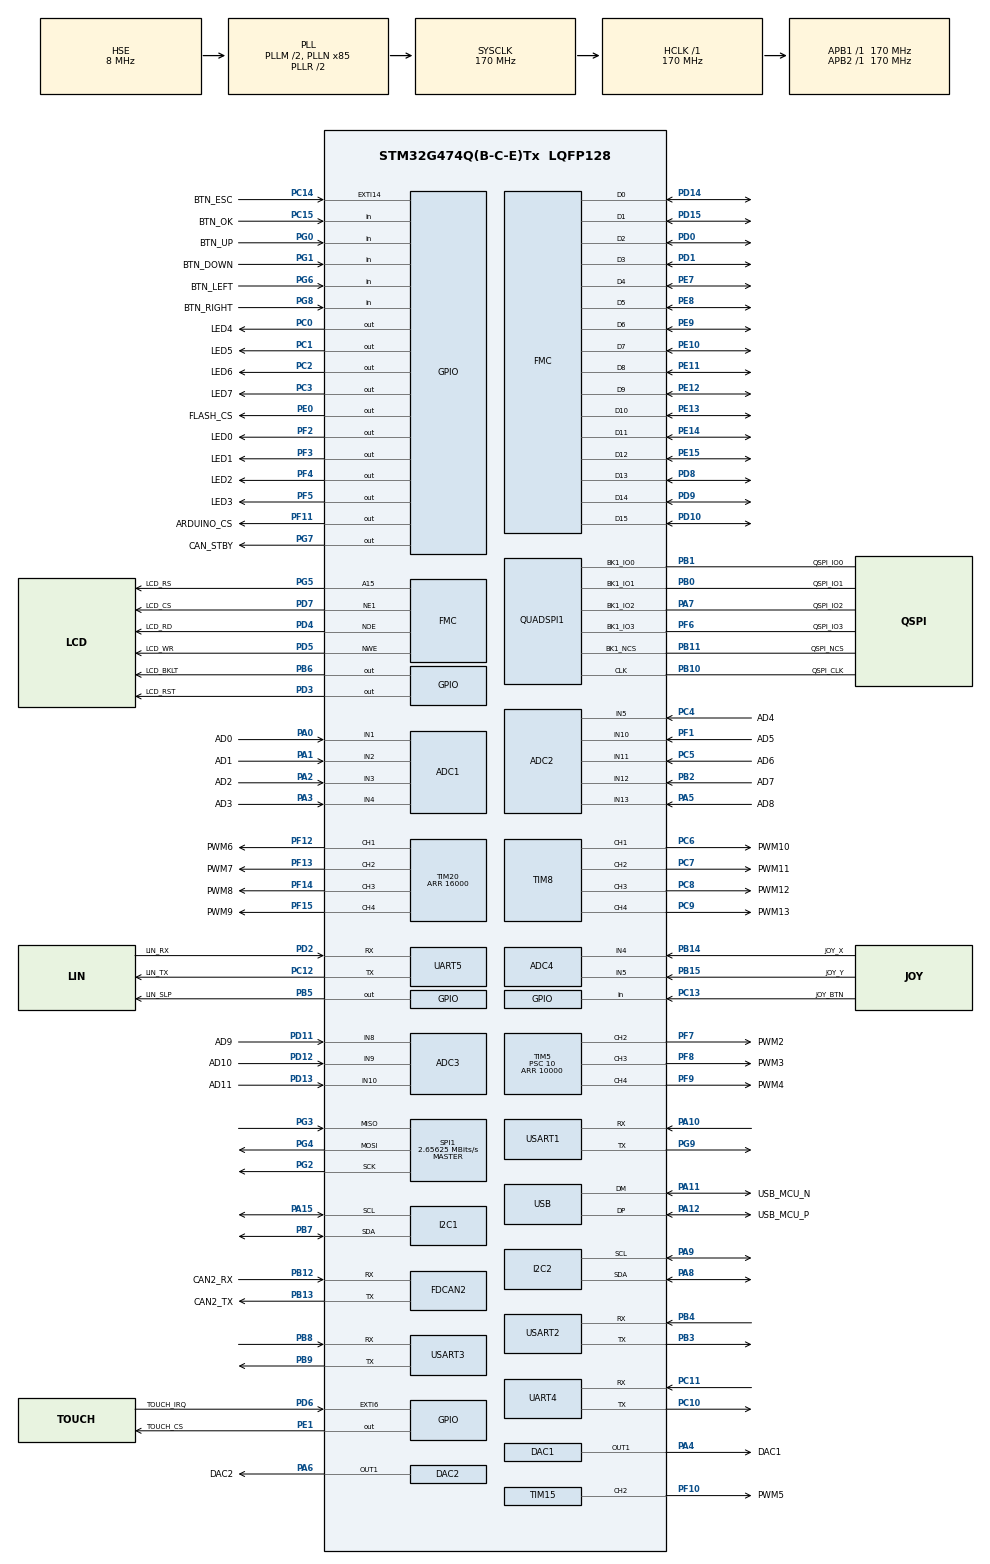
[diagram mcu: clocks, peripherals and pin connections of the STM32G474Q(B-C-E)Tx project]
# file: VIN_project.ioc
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ADC1.Channel-0\#ChannelRegularConversion=ADC_CHANNEL_2
ADC1.NbrOfConversionFlag=1
ADC1.OffsetNumber-0\#ChannelRegularConversion=ADC_OFFSET_NONE
ADC1.Rank-0\#ChannelRegularConversion=1
ADC1.SamplingTime-0\#ChannelRegularConversion=ADC_SAMPLETIME_2CYCLES_5
ADC1.master=1
ADC2.Channel-0\#ChannelRegularConversion=ADC_CHANNEL_5
ADC2.NbrOfConversionFlag=1
ADC2.OffsetNumber-0\#ChannelRegularConversion=ADC_OFFSET_NONE
ADC2.Rank-0\#ChannelRegularConversion=1
ADC2.SamplingTime-0\#ChannelRegularConversion=ADC_SAMPLETIME_2CYCLES_5
ADC3.Channel-1\#ChannelRegularConversion=ADC_CHANNEL_8
ADC3.NbrOfConversionFlag=1
ADC3.OffsetNumber-1\#ChannelRegularConversion=ADC_OFFSET_NONE
ADC3.Rank-1\#ChannelRegularConversion=1
ADC3.SamplingTime-1\#ChannelRegularConversion=ADC_SAMPLETIME_2CYCLES_5
ADC3.master=1
ADC4.Channel-0\#ChannelRegularConversion=ADC_CHANNEL_4
ADC4.Channel-1\#ChannelRegularConversion=ADC_CHANNEL_5
ADC4.ContinuousConvMode=DISABLE
ADC4.DMAContinuousRequests=DISABLE
ADC4.DiscontinuousConvMode=ENABLE
ADC4.EOCSelection=ADC_EOC_SINGLE_CONV
ADC4.NbrOfConversion=2
ADC4.NbrOfConversionFlag=1
ADC4.OffsetNumber-0\#ChannelRegularConversion=ADC_OFFSET_NONE
ADC4.OffsetNumber-1\#ChannelRegularConversion=ADC_OFFSET_NONE
ADC4.Overrun=ADC_OVR_DATA_OVERWRITTEN
ADC4.Rank-0\#ChannelRegularConversion=1
ADC4.Rank-1\#ChannelRegularConversion=2
ADC4.SamplingTime-0\#ChannelRegularConversion=ADC_SAMPLETIME_92CYCLES_5
ADC4.SamplingTime-1\#ChannelRegularConversion=ADC_SAMPLETIME_92CYCLES_5
Dma.Request0=USART1_RX
Dma.Request1=USART1_TX
Dma.USART1_RX.0.Direction=DMA_PERIPH_TO_MEMORY
Dma.USART1_RX.0.EventEnable=DISABLE
Dma.USART1_RX.0.Instance=DMA1_Channel1
Dma.USART1_RX.0.MemDataAlignment=DMA_MDATAALIGN_BYTE
Dma.USART1_RX.0.MemInc=DMA_MINC_ENABLE
Dma.USART1_RX.0.Mode=DMA_NORMAL
Dma.USART1_RX.0.PeriphDataAlignment=DMA_PDATAALIGN_BYTE
Dma.USART1_RX.0.PeriphInc=DMA_PINC_DISABLE
Dma.USART1_RX.0.Polarity=HAL_DMAMUX_REQ_GEN_RISING
Dma.USART1_RX.0.Priority=DMA_PRIORITY_LOW
Dma.USART1_RX.0.RequestNumber=1
Dma.USART1_RX.0.SignalID=NONE
Dma.USART1_RX.0.SyncEnable=DISABLE
Dma.USART1_RX.0.SyncPolarity=HAL_DMAMUX_SYNC_NO_EVENT
Dma.USART1_RX.0.SyncRequestNumber=1
Dma.USART1_RX.0.SyncSignalID=NONE
Dma.USART1_TX.1.Direction=DMA_MEMORY_TO_PERIPH
Dma.USART1_TX.1.EventEnable=DISABLE
Dma.USART1_TX.1.Instance=DMA1_Channel2
Dma.USART1_TX.1.MemDataAlignment=DMA_MDATAALIGN_BYTE
Dma.USART1_TX.1.MemInc=DMA_MINC_ENABLE
Dma.USART1_TX.1.Mode=DMA_NORMAL
Dma.USART1_TX.1.PeriphDataAlignment=DMA_PDATAALIGN_BYTE
Dma.USART1_TX.1.PeriphInc=DMA_PINC_DISABLE
Dma.USART1_TX.1.Polarity=HAL_DMAMUX_REQ_GEN_RISING
Dma.USART1_TX.1.Priority=DMA_PRIORITY_LOW
Dma.USART1_TX.1.RequestNumber=1
Dma.USART1_TX.1.SignalID=NONE
Dma.USART1_TX.1.SyncEnable=DISABLE
Dma.USART1_TX.1.SyncPolarity=HAL_DMAMUX_SYNC_NO_EVENT
Dma.USART1_TX.1.SyncRequestNumber=1
Dma.USART1_TX.1.SyncSignalID=NONE
FMC.AddressSetupTime1=1
FMC.BusTurnAroundDuration1=1
FMC.DataHoldTime1=1
FMC.DataSetupTime1=1
FMC.ExtendedMode1=FMC_EXTENDED_MODE_DISABLE
I2C1.Timing=0x30A0A7FB
I2C2.Timing=0x30A0A7FB
Mcu.Family=STM32G4
Mcu.Name=STM32G474Q(B-C-E)Tx
Mcu.Package=LQFP128
NVIC.DMA1_Channel1_IRQn=true\:0\:0\:false\:false\:true\:false\:true\:true
NVIC.DMA1_Channel2_IRQn=true\:0\:0\:false\:false\:true\:false\:true\:true
NVIC.EXTI15_10_IRQn=true\:0\:0\:true\:false\:true\:true\:true\:true
NVIC.EXTI9_5_IRQn=true\:0\:0\:false\:false\:true\:true\:true\:true
NVIC.PriorityGroup=NVIC_PRIORITYGROUP_4
NVIC.TIM6_DAC_IRQn=true\:15\:0\:true\:false\:true\:true\:true\:true
NVIC.USB_LP_IRQn=true\:0\:0\:false\:false\:true\:false\:true\:true
PA0.GPIO_Label=AD0
PA0.Mode=IN1-Single-Ended
PA0.Signal=ADC1_IN1
PA1.GPIO_Label=AD1
PA1.Mode=IN2-Single-Ended
PA1.Signal=ADC1_IN2
PA10.Mode=Asynchronous
PA10.Signal=USART1_RX
PA11.GPIO_Label=USB_MCU_N
PA11.Mode=Device
PA11.Signal=USB_DM
PA12.GPIO_Label=USB_MCU_P
PA12.Mode=Device
PA12.Signal=USB_DP
PA13.GPIO_Label=SWDIO
PA13.Mode=Trace_Synchro_4bits_SW
PA13.Signal=SYS_JTMS-SWDIO
PA14.GPIO_Label=SWCLK
PA14.Mode=Trace_Synchro_4bits_SW
PA14.Signal=SYS_JTCK-SWCLK
PA15.Mode=I2C
PA15.Signal=I2C1_SCL
PA2.GPIO_Label=AD2
PA2.Mode=IN3-Single-Ended
PA2.Signal=ADC1_IN3
PA3.GPIO_Label=AD3
PA3.Mode=IN4-Single-Ended
PA3.Signal=ADC1_IN4
PA4.GPIO_Label=DAC1
PA4.Signal=COMP_DAC11_group
PA5.GPIO_Label=AD8
PA5.Mode=IN13-Single-Ended
PA5.Signal=ADC2_IN13
PA6.GPIO_Label=DAC2
PA6.Signal=COMP_DAC21_group
PA7.GPIO_Label=QSPI_IO2
PA7.Mode=Single Bank 1
PA7.Signal=QUADSPI1_BK1_IO2
PA8.GPIO_Pu=GPIO_PULLUP
PA8.Mode=I2C
PA8.Signal=I2C2_SDA
PA9.GPIO_Pu=GPIO_PULLUP
PA9.Mode=I2C
PA9.Signal=I2C2_SCL
PB0.GPIO_Label=QSPI_IO1
PB0.Mode=Single Bank 1
PB0.Signal=QUADSPI1_BK1_IO1
PB1.GPIO_Label=QSPI_IO0
PB1.Mode=Single Bank 1
PB1.Signal=QUADSPI1_BK1_IO0
PB10.GPIO_Label=QSPI_CLK
PB10.Mode=Single Bank 1
PB10.Signal=QUADSPI1_CLK
PB11.GPIO_Label=QSPI_NCS
PB11.Mode=Single Bank 1
PB11.Signal=QUADSPI1_BK1_NCS
PB12.GPIO_Label=CAN2_RX
PB12.Mode=FDCAN_Activate
PB12.Signal=FDCAN2_RX
PB13.GPIO_Label=CAN2_TX
PB13.Mode=FDCAN_Activate
PB13.Signal=FDCAN2_TX
PB14.GPIO_Label=JOY_X
PB14.Mode=IN4-Single-Ended
PB14.Signal=ADC4_IN4
PB15.GPIO_Label=JOY_Y
PB15.Mode=IN5-Single-Ended
PB15.Signal=ADC4_IN5
PB2.GPIO_Label=AD7
PB2.Mode=IN12-Single-Ended
PB2.Signal=ADC2_IN12
PB3.Mode=Asynchronous
PB3.Signal=USART2_TX
PB4.Mode=Asynchronous
PB4.Signal=USART2_RX
PB5.GPIO_Label=LIN_SLP
PB5.Signal=GPIO_Output
PB6.GPIO_Label=LCD_BKLT
PB6.Signal=GPIO_Output
PB7.Mode=I2C
PB7.Signal=I2C1_SDA
PB8-BOOT0.Mode=Asynchronous
PB8-BOOT0.Signal=USART3_RX
PB9.Mode=Asynchronous
PB9.Signal=USART3_TX
PC0.GPIO_Label=LED4
PC0.Signal=GPIO_Output
PC1.GPIO_Label=LED5
PC1.Signal=GPIO_Output
PC10.Mode=Asynchronous
PC10.Signal=UART4_TX
PC11.Mode=Asynchronous
PC11.Signal=UART4_RX
PC12.GPIO_Label=LIN_TX
PC12.Mode=Asynchronous
PC12.Signal=UART5_TX
PC13.GPIO_Label=JOY_BTN
PC13.GPIO_PuPd=GPIO_PULLUP
PC13.Signal=GPIO_Input
PC14-OSC32_IN.GPIO_Label=BTN_ESC
PC14-OSC32_IN.GPIO_ModeDefaultEXTI=GPIO_MODE_IT_FALLING
PC14-OSC32_IN.GPIO_PuPd=GPIO_PULLUP
PC14-OSC32_IN.Signal=GPXTI14
PC15-OSC32_OUT.GPIO_Label=BTN_OK
PC15-OSC32_OUT.GPIO_PuPd=GPIO_PULLUP
PC15-OSC32_OUT.Signal=GPIO_Input
PC2.GPIO_Label=LED6
PC2.Signal=GPIO_Output
PC3.GPIO_Label=LED7
PC3.Signal=GPIO_Output
PC4.GPIO_Label=AD4
PC4.Mode=IN5-Single-Ended
PC4.Signal=ADC2_IN5
PC5.GPIO_Label=AD6
PC5.Mode=IN11-Single-Ended
PC5.Signal=ADC2_IN11
PC6.GPIO_Label=PWM10
PC6.Signal=S_TIM8_CH1
PC7.GPIO_Label=PWM11
PC7.Signal=S_TIM8_CH2
PC8.GPIO_Label=PWM12
PC8.Signal=S_TIM8_CH3
PC9.GPIO_Label=PWM13
PC9.Signal=S_TIM8_CH4
PD0.Signal=FMC_D2_DA2
PD1.Signal=FMC_D3_DA3
PD10.Signal=FMC_D15_DA15
PD11.GPIO_Label=AD9
PD11.GPIO_Mode=GPIO_MODE_ANALOG
PD11.GPIO_PuPd=GPIO_NOPULL
PD11.Mode=IN8-Single-Ended
PD11.Signal=ADC3_IN8
PD12.GPIO_Label=AD10
PD12.GPIO_Mode=GPIO_MODE_ANALOG
PD12.GPIO_PuPd=GPIO_NOPULL
PD12.Mode=IN9-Single-Ended
PD12.Signal=ADC3_IN9
PD13.GPIO_Label=AD11
PD13.GPIO_Mode=GPIO_MODE_ANALOG
PD13.GPIO_PuPd=GPIO_NOPULL
PD13.Mode=IN10-Single-Ended
PD13.Signal=ADC3_IN10
PD14.Signal=FMC_D0_DA0
PD15.Signal=FMC_D1_DA1
PD2.GPIO_Label=LIN_RX
PD2.Mode=Asynchronous
PD2.Signal=UART5_RX
PD3.GPIO_Label=LCD_RST
PD3.Signal=GPIO_Output
PD4.GPIO_Label=LCD_RD
PD4.Signal=FMC_NOE
PD5.GPIO_Label=LCD_WR
PD5.Signal=FMC_NWE
PD6.GPIO_Label=TOUCH_IRQ
PD6.GPIO_ModeDefaultEXTI=GPIO_MODE_IT_FALLING
PD6.GPIO_PuPd=GPIO_PULLUP
PD6.Signal=GPXTI6
PD7.GPIO_Label=LCD_CS
PD7.Mode=NorPsramChipSelect1_1
PD7.Signal=FMC_NE1
PD8.Signal=FMC_D13_DA13
PD9.Signal=FMC_D14_DA14
PE0.GPIO_Label=FLASH_CS
PE0.Signal=GPIO_Output
PE1.GPIO_Label=TOUCH_CS
PE1.GPIO_PuPd=GPIO_PULLUP
PE1.GPIO_Speed=GPIO_SPEED_FREQ_HIGH
PE1.PinState=GPIO_PIN_SET
PE1.Signal=GPIO_Output
PE10.Signal=FMC_D7_DA7
PE11.Signal=FMC_D8_DA8
PE12.Signal=FMC_D9_DA9
PE13.Signal=FMC_D10_DA10
PE14.Signal=FMC_D11_DA11
PE15.Signal=FMC_D12_DA12
PE2.Mode=Trace_Synchro_4bits_SW
PE2.Signal=SYS_TRACECLK
PE3.Mode=Trace_Synchro_4bits_SW
PE3.Signal=SYS_TRACED0
PE4.Mode=Trace_Synchro_4bits_SW
PE4.Signal=SYS_TRACED1
PE5.Mode=Trace_Synchro_4bits_SW
PE5.Signal=SYS_TRACED2
PE6.Mode=Trace_Synchro_4bits_SW
PE6.Signal=SYS_TRACED3
PE7.Signal=FMC_D4_DA4
PE8.Signal=FMC_D5_DA5
PE9.Signal=FMC_D6_DA6
PF0-OSC_IN.GPIO_Label=MCI
PF0-OSC_IN.Mode=HSE-External-Clock-Source
PF0-OSC_IN.Signal=RCC_OSC_IN
PF1-OSC_OUT.GPIO_Label=AD5
PF1-OSC_OUT.Mode=IN10-Single-Ended
PF1-OSC_OUT.Signal=ADC2_IN10
PF10.GPIO_Label=PWM5
PF10.Signal=S_TIM15_CH2
PF11.GPIO_Label=ARDUINO_CS
PF11.Signal=GPIO_Output
PF12.GPIO_Label=PWM6
PF12.Mode=PWM Generation1 CH1
PF12.Signal=TIM20_CH1
PF13.GPIO_Label=PWM7
PF13.Signal=S_TIM20_CH2
PF14.GPIO_Label=PWM8
PF14.Signal=S_TIM20_CH3
PF15.GPIO_Label=PWM9
PF15.Signal=S_TIM20_CH4
PF2.GPIO_Label=LED0
PF2.GPIO_Speed=GPIO_SPEED_FREQ_VERY_HIGH
PF2.Signal=GPIO_Output
PF3.GPIO_Label=LED1
PF3.Signal=GPIO_Output
PF4.GPIO_Label=LED2
PF4.Signal=GPIO_Output
PF5.GPIO_Label=LED3
PF5.Signal=GPIO_Output
PF6.GPIO_Label=QSPI_IO3
PF6.Mode=Single Bank 1
PF6.Signal=QUADSPI1_BK1_IO3
PF7.GPIO_Label=PWM2
PF7.Signal=S_TIM5_CH2
PF8.GPIO_Label=PWM3
PF8.Signal=S_TIM5_CH3
PF9.GPIO_Label=PWM4
PF9.Signal=S_TIM5_CH4
PG0.GPIO_Label=BTN_UP
PG0.GPIO_PuPd=GPIO_PULLUP
PG0.Signal=GPIO_Input
PG1.GPIO_Label=BTN_DOWN
PG1.GPIO_PuPd=GPIO_PULLUP
PG1.Signal=GPIO_Input
PG2.Mode=Full_Duplex_Master
PG2.Signal=SPI1_SCK
PG3.Mode=Full_Duplex_Master
PG3.Signal=SPI1_MISO
PG4.Mode=Full_Duplex_Master
PG4.Signal=SPI1_MOSI
PG5.GPIO_Label=LCD_RS
PG5.Signal=FMC_A15
PG6.GPIO_Label=BTN_LEFT
PG6.GPIO_PuPd=GPIO_PULLUP
PG6.Signal=GPIO_Input
PG7.GPIO_Label=CAN_STBY
PG7.Signal=GPIO_Output
PG8.GPIO_Label=BTN_RIGHT
PG8.GPIO_PuPd=GPIO_PULLUP
PG8.Signal=GPIO_Input
PG9.Mode=Asynchronous
PG9.Signal=USART1_TX
ProjectManager.HeapSize=0x200
ProjectManager.StackSize=0x400
ProjectManager.TargetToolchain=STM32CubeIDE
RCC.ADC12Freq_Value=170000000
RCC.ADC345Freq_Value=170000000
RCC.AHBFreq_Value=170000000
RCC.APB1Freq_Value=170000000
RCC.APB1TimFreq_Value=170000000
RCC.APB2Freq_Value=170000000
RCC.APB2TimFreq_Value=170000000
RCC.CK48CLockSelection=RCC_USBCLKSOURCE_HSI48
RCC.CortexFreq_Value=170000000
RCC.EXTERNAL_CLOCK_VALUE=12288000
RCC.HCLKFreq_Value=170000000
RCC.HSE_VALUE=8000000
RCC.HSI48_VALUE=48000000
RCC.HSI_VALUE=16000000
RCC.LSE_VALUE=32768
RCC.PLLM=RCC_PLLM_DIV2
RCC.PLLN=85
RCC.PLLQ=RCC_PLLQ_DIV6
RCC.PLLSourceVirtual=RCC_PLLSOURCE_HSE
RCC.SYSCLKFreq_VALUE=170000000
RCC.SYSCLKSource=RCC_SYSCLKSOURCE_PLLCLK
RCC.USBFreq_Value=48000000
RCC.VCOOutputFreq_Value=340000000
SH.COMP_DAC11_group.0=DAC1_OUT1,DAC_OUT1
SH.COMP_DAC21_group.0=DAC2_OUT1,DAC_OUT1
SH.FMC_A15.0=FMC_A15,A15_1
SH.FMC_D0_DA0.0=FMC_D0,16b-d1
SH.FMC_D10_DA10.0=FMC_D10,16b-d1
SH.FMC_D11_DA11.0=FMC_D11,16b-d1
SH.FMC_D12_DA12.0=FMC_D12,16b-d1
SH.FMC_D13_DA13.0=FMC_D13,16b-d1
SH.FMC_D14_DA14.0=FMC_D14,16b-d1
SH.FMC_D15_DA15.0=FMC_D15,16b-d1
SH.FMC_D1_DA1.0=FMC_D1,16b-d1
SH.FMC_D2_DA2.0=FMC_D2,16b-d1
SH.FMC_D3_DA3.0=FMC_D3,16b-d1
SH.FMC_D4_DA4.0=FMC_D4,16b-d1
SH.FMC_D5_DA5.0=FMC_D5,16b-d1
SH.FMC_D6_DA6.0=FMC_D6,16b-d1
SH.FMC_D7_DA7.0=FMC_D7,16b-d1
SH.FMC_D8_DA8.0=FMC_D8,16b-d1
SH.FMC_D9_DA9.0=FMC_D9,16b-d1
SH.FMC_NOE.0=FMC_NOE,Lcd1
SH.FMC_NWE.0=FMC_NWE,Lcd1
SH.S_TIM15_CH2.0=TIM15_CH2,PWM Generation2 CH2
SH.S_TIM20_CH2.0=TIM20_CH2,PWM Generation2 CH2
SH.S_TIM20_CH3.0=TIM20_CH3,PWM Generation3 CH3
SH.S_TIM20_CH4.0=TIM20_CH4,PWM Generation4 CH4
SH.S_TIM5_CH2.0=TIM5_CH2,PWM Generation2 CH2
SH.S_TIM5_CH3.0=TIM5_CH3,PWM Generation3 CH3
SH.S_TIM5_CH4.0=TIM5_CH4,PWM Generation4 CH4
SH.S_TIM8_CH1.0=TIM8_CH1,PWM Generation1 CH1
SH.S_TIM8_CH2.0=TIM8_CH2,PWM Generation2 CH2
SH.S_TIM8_CH3.0=TIM8_CH3,PWM Generation3 CH3
SH.S_TIM8_CH4.0=TIM8_CH4,PWM Generation4 CH4
SPI1.BaudRatePrescaler=SPI_BAUDRATEPRESCALER_64
SPI1.CalculateBaudRate=2.65625 MBits/s
SPI1.DataSize=SPI_DATASIZE_8BIT
SPI1.Direction=SPI_DIRECTION_2LINES
SPI1.Mode=SPI_MODE_MASTER
SPI1.NSSPMode=SPI_NSS_PULSE_DISABLE
SPI1.VirtualType=VM_MASTER
STMicroelectronics.X-CUBE-DISPLAY.2.0.0.BSP.number=2
STMicroelectronics.X-CUBE-DISPLAY.2.0.0.p_display_cache_lines=4
STMicroelectronics.X-CUBE-DISPLAY.2.0.0.p_fmc_dma_tx_id=1\:1
STMicroelectronics.X-CUBE-DISPLAY.2.0.00.BSP.STBoard=false
STMicroelectronics.X-CUBE-DISPLAY.2.0.00.BSP.api=Unknown
STMicroelectronics.X-CUBE-DISPLAY.2.0.00.BSP.condition=(SEMBoardOoPartJjLCDJjILI9341JjSPI | SEMBoardOoPartJjLCDJjILI9341JjFMC)
STMicroelectronics.X-CUBE-DISPLAY.2.0.00.BSP.i2caddr=0
STMicroelectronics.X-CUBE-DISPLAY.2.0.00.BSP.instance=PD3
STMicroelectronics.X-CUBE-DISPLAY.2.0.00.BSP.ip=GPIO
STMicroelectronics.X-CUBE-DISPLAY.2.0.00.BSP.mode=Output
STMicroelectronics.X-CUBE-DISPLAY.2.0.00.BSP.name=LCD RESET Pin
STMicroelectronics.X-CUBE-DISPLAY.2.0.00.BSP.solution=PD3
STMicroelectronics.X-CUBE-DISPLAY.2.0.01.BSP.STBoard=false
STMicroelectronics.X-CUBE-DISPLAY.2.0.01.BSP.api=HAL_EXTI_DRIVER
STMicroelectronics.X-CUBE-DISPLAY.2.0.01.BSP.condition=(SEMBoardOoPartJjLCDJjILI9341JjSPI | SEMBoardOoPartJjLCDJjILI9341JjFMC)
STMicroelectronics.X-CUBE-DISPLAY.2.0.01.BSP.i2caddr=0
STMicroelectronics.X-CUBE-DISPLAY.2.0.01.BSP.instance=PC14-OSC32_IN
STMicroelectronics.X-CUBE-DISPLAY.2.0.01.BSP.ip=GPIO
STMicroelectronics.X-CUBE-DISPLAY.2.0.01.BSP.mode=EXTI
STMicroelectronics.X-CUBE-DISPLAY.2.0.01.BSP.name=LCD TE Pin
STMicroelectronics.X-CUBE-DISPLAY.2.0.01.BSP.solution=PC14-OSC32_IN
STMicroelectronics.X-CUBE-TOUCHGFX.4.18.0.tgfx_buffering_strategy=Partial
STMicroelectronics.X-CUBE-TOUCHGFX.4.18.0.tgfx_custom_height=240
STMicroelectronics.X-CUBE-TOUCHGFX.4.18.0.tgfx_custom_width=320
STMicroelectronics.X-CUBE-TOUCHGFX.4.18.0.tgfx_display_interface=disp_fmc
STMicroelectronics.X-CUBE-TOUCHGFX.4.18.0.tgfx_hardware_accelerator=dma_none
STMicroelectronics.X-CUBE-TOUCHGFX.4.18.0_IsPackSelfContextualization=true
TIM15.Channel-PWM\ Generation2\ CH2=TIM_CHANNEL_2
TIM15.PeriodNoDither=32768
TIM15.PulseNoDither_2=16000
TIM20.Channel-PWM\ Generation1\ CH1=TIM_CHANNEL_1
TIM20.Channel-PWM\ Generation2\ CH2=TIM_CHANNEL_2
TIM20.Channel-PWM\ Generation3\ CH3=TIM_CHANNEL_3
TIM20.Channel-PWM\ Generation4\ CH4=TIM_CHANNEL_4
TIM20.PeriodNoDither=16000
TIM20.PulseNoDither_1=8000
TIM20.PulseNoDither_2=10000
TIM20.PulseNoDither_3=12000
TIM20.PulseNoDither_4=15000
TIM5.AutoReloadPreload=TIM_AUTORELOAD_PRELOAD_ENABLE
TIM5.Channel-PWM\ Generation2\ CH2=TIM_CHANNEL_2
TIM5.Channel-PWM\ Generation3\ CH3=TIM_CHANNEL_3
TIM5.Channel-PWM\ Generation4\ CH4=TIM_CHANNEL_4
TIM5.PeriodNoDither=10000
TIM5.Prescaler=10
TIM5.PulseNoDither_2=200
TIM5.PulseNoDither_3=400
TIM5.PulseNoDither_4=600
TIM6.AutoReloadPreload=TIM_AUTORELOAD_PRELOAD_ENABLE
TIM6.PeriodNoDither=49999
TIM6.Prescaler=170
TIM8.Channel-PWM\ Generation1\ CH1=TIM_CHANNEL_1
TIM8.Channel-PWM\ Generation2\ CH2=TIM_CHANNEL_2
TIM8.Channel-PWM\ Generation3\ CH3=TIM_CHANNEL_3
TIM8.Channel-PWM\ Generation4\ CH4=TIM_CHANNEL_4
TIM8.PulseNoDither_1=1000
TIM8.PulseNoDither_2=2000
TIM8.PulseNoDither_3=4000
TIM8.PulseNoDither_4=8000
USART1.VirtualMode-Asynchronous=VM_ASYNC
USART2.VirtualMode-Asynchronous=VM_ASYNC
USART3.VirtualMode-Asynchronous=VM_ASYNC
USB_DEVICE.CLASS_NAME_FS=CDC
USB_DEVICE.VirtualMode=Cdc
USB_DEVICE.VirtualModeFS=Cdc_FS
VP_CRC_VS_CRC.Mode=CRC_Activate
VP_SYS_VS_DBSignals.Mode=DisableDeadBatterySignals
VP_TIM15_VS_ClockSourceINT.Mode=Internal
VP_TIM20_VS_ClockSourceINT.Mode=Internal
VP_TIM5_VS_ClockSourceINT.Mode=Internal
VP_TIM6_VS_ClockSourceINT.Mode=Enable_Timer
VP_TIM8_VS_ClockSourceINT.Mode=Internal
VP_USB_DEVICE_VS_USB_DEVICE_CDC_FS.Mode=CDC_FS
board=custom

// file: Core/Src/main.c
/* USER CODE BEGIN Header */
/**
  ******************************************************************************
  * @file           : main.c
  * @brief          : Main program body
  ******************************************************************************
  * @attention
  *
  * Copyright (c) 2022 STMicroelectronics.
  * All rights reserved.
  *
  * This software is licensed under terms that can be found in the LICENSE file
  * in the root directory of this software component.
  * If no LICENSE file comes with this software, it is provided AS-IS.
  *
  ******************************************************************************
  */
/* USER CODE END Header */
#include "main.h"
#include "adc.h"
#include "crc.h"
#include "dac.h"
#include "dma.h"
#include "fdcan.h"
#include "i2c.h"
#include "quadspi.h"
#include "spi.h"
#include "tim.h"
#include "usart.h"
#include "usb_device.h"
#include "gpio.h"
#include "fmc.h"

/* USER CODE BEGIN Includes */
#include "stm32g4xx_hal_conf.h"
#include "game.h"

/* USER CODE END Includes */

void SystemClock_Config(void);

int main(void)
{

  /* MCU Configuration--------------------------------------------------------*/

  /* Reset of all peripherals, Initializes the Flash interface and the Systick. */
  HAL_Init();

  /* Configure the system clock */
  SystemClock_Config();

  /* Initialize all configured peripherals */
  MX_GPIO_Init();
  MX_ADC1_Init();
  MX_ADC2_Init();
  MX_FMC_Init();
  MX_I2C2_Init();
  MX_UART4_Init();
  MX_UART5_Init();
  MX_USART1_UART_Init();
  MX_USART2_UART_Init();
  MX_QUADSPI1_Init();
  MX_SPI1_Init();
  MX_TIM5_Init();
  MX_TIM8_Init();
  MX_TIM20_Init();
  MX_ADC3_Init();
  MX_DAC1_Init();
  MX_DAC2_Init();
  MX_FDCAN2_Init();
  MX_I2C1_Init();
  MX_TIM15_Init();
  MX_USART3_UART_Init();
  MX_ADC4_Init();
  MX_USB_Device_Init();
  MX_DMA_Init();
  MX_CRC_Init();
  MX_TIM6_Init();
  /* USER CODE BEGIN 2 */

  game_init();

  uint32_t frameRate = 60;
  uint32_t frameTime = 1000 / frameRate;
  uint32_t prev = HAL_GetTick();
  /* USER CODE END 2 */

  /* Infinite loop */
  while (1)
  {

    /* USER CODE BEGIN 3 */
	  uint32_t curr = HAL_GetTick();
	  uint32_t diff = curr - prev;
	  prev = curr;

	  gameState.ticks = curr;
	  gameState.deltaTicks = diff;

	  gameState.time = (f32)gameState.ticks / 1000.0f;
	  gameState.deltaTime = (f32)gameState.deltaTicks / 1000.0f;

	  game_tick();
  }
  /* USER CODE END 3 */
}

void SystemClock_Config(void)
{
  RCC_OscInitTypeDef RCC_OscInitStruct = {0};
  RCC_ClkInitTypeDef RCC_ClkInitStruct = {0};

  /** Configure the main internal regulator output voltage
  */
  HAL_PWREx_ControlVoltageScaling(PWR_REGULATOR_VOLTAGE_SCALE1_BOOST);

  /** Initializes the RCC Oscillators according to the specified parameters
  * in the RCC_OscInitTypeDef structure.
  */
  RCC_OscInitStruct.OscillatorType = RCC_OSCILLATORTYPE_HSI48|RCC_OSCILLATORTYPE_HSE;
  RCC_OscInitStruct.HSEState = RCC_HSE_BYPASS;
  RCC_OscInitStruct.HSI48State = RCC_HSI48_ON;
  RCC_OscInitStruct.PLL.PLLState = RCC_PLL_ON;
  RCC_OscInitStruct.PLL.PLLSource = RCC_PLLSOURCE_HSE;
  RCC_OscInitStruct.PLL.PLLM = RCC_PLLM_DIV2;
  RCC_OscInitStruct.PLL.PLLN = 85;
  RCC_OscInitStruct.PLL.PLLP = RCC_PLLP_DIV2;
  RCC_OscInitStruct.PLL.PLLQ = RCC_PLLQ_DIV6;
  RCC_OscInitStruct.PLL.PLLR = RCC_PLLR_DIV2;
  if (HAL_RCC_OscConfig(&RCC_OscInitStruct) != HAL_OK)
  {
    Error_Handler();
  }

  /** Initializes the CPU, AHB and APB buses clocks
  */
  RCC_ClkInitStruct.ClockType = RCC_CLOCKTYPE_HCLK|RCC_CLOCKTYPE_SYSCLK
                              |RCC_CLOCKTYPE_PCLK1|RCC_CLOCKTYPE_PCLK2;
  RCC_ClkInitStruct.SYSCLKSource = RCC_SYSCLKSOURCE_PLLCLK;
  RCC_ClkInitStruct.AHBCLKDivider = RCC_SYSCLK_DIV1;
  RCC_ClkInitStruct.APB1CLKDivider = RCC_HCLK_DIV1;
  RCC_ClkInitStruct.APB2CLKDivider = RCC_HCLK_DIV1;

  if (HAL_RCC_ClockConfig(&RCC_ClkInitStruct, FLASH_LATENCY_4) != HAL_OK)
  {
    Error_Handler();
  }
}

void Error_Handler(void)
{
  __disable_irq();
  while (1)
  {
  }
}

#ifdef  USE_FULL_ASSERT
/**
  * @brief  Reports the name of the source file and the source line number
  *         where the assert_param error has occurred.
  * @param  file: pointer to the source file name
  * @param  line: assert_param error line source number
  * @retval None
  */
void assert_failed(uint8_t *file, uint32_t line)
{
  /* USER CODE BEGIN 6 */
  /* User can add his own implementation to report the file name and line number,
     ex: printf("Wrong parameters value: file %s on line %d\r\n", file, line) */
	char assertString[128];
	snprintf(assertString, "Assert failed(File: %s, Line: %d)\r\n", (char*)file, line);
	CDC_Transmit_FS(assertString, strlen(assertString));
	while (1) {

	}
  /* USER CODE END 6 */
}
#endif /* USE_FULL_ASSERT */
